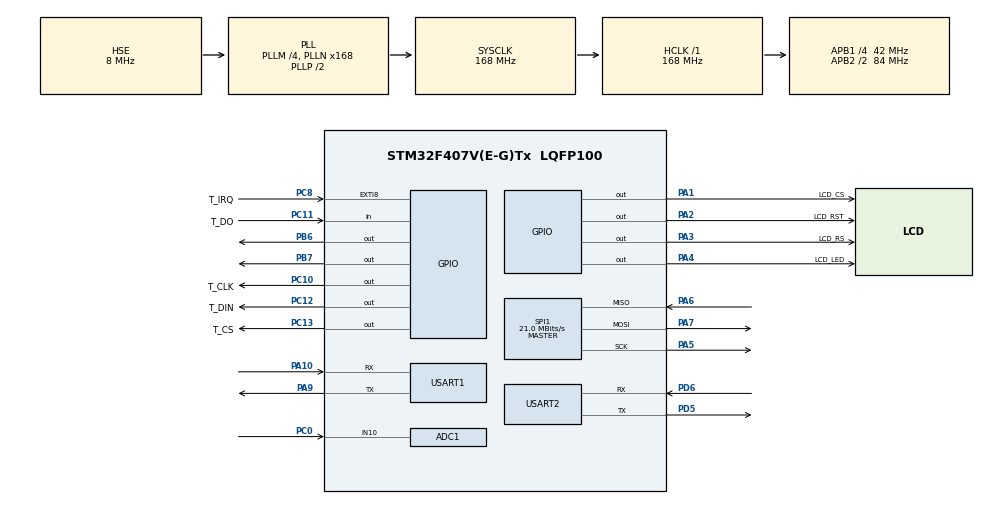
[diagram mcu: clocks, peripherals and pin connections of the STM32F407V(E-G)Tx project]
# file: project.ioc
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ADC1.Channel-0\#ChannelRegularConversion=ADC_CHANNEL_10
ADC1.NbrOfConversionFlag=1
ADC1.Rank-0\#ChannelRegularConversion=1
ADC1.SamplingTime-0\#ChannelRegularConversion=ADC_SAMPLETIME_3CYCLES
ADC1.master=1
Dma.Request0=USART1_TX
Dma.Request1=SPI1_TX
Dma.Request2=SPI1_RX
Dma.SPI1_RX.2.Direction=DMA_PERIPH_TO_MEMORY
Dma.SPI1_RX.2.FIFOMode=DMA_FIFOMODE_DISABLE
Dma.SPI1_RX.2.Instance=DMA2_Stream0
Dma.SPI1_RX.2.MemDataAlignment=DMA_MDATAALIGN_BYTE
Dma.SPI1_RX.2.MemInc=DMA_MINC_ENABLE
Dma.SPI1_RX.2.Mode=DMA_NORMAL
Dma.SPI1_RX.2.PeriphDataAlignment=DMA_PDATAALIGN_BYTE
Dma.SPI1_RX.2.PeriphInc=DMA_PINC_DISABLE
Dma.SPI1_RX.2.Priority=DMA_PRIORITY_MEDIUM
Dma.SPI1_TX.1.Direction=DMA_MEMORY_TO_PERIPH
Dma.SPI1_TX.1.FIFOMode=DMA_FIFOMODE_DISABLE
Dma.SPI1_TX.1.Instance=DMA2_Stream3
Dma.SPI1_TX.1.MemDataAlignment=DMA_MDATAALIGN_BYTE
Dma.SPI1_TX.1.MemInc=DMA_MINC_ENABLE
Dma.SPI1_TX.1.Mode=DMA_NORMAL
Dma.SPI1_TX.1.PeriphDataAlignment=DMA_PDATAALIGN_BYTE
Dma.SPI1_TX.1.PeriphInc=DMA_PINC_DISABLE
Dma.SPI1_TX.1.Priority=DMA_PRIORITY_MEDIUM
Dma.USART1_TX.0.Direction=DMA_MEMORY_TO_PERIPH
Dma.USART1_TX.0.FIFOMode=DMA_FIFOMODE_DISABLE
Dma.USART1_TX.0.Instance=DMA2_Stream7
Dma.USART1_TX.0.MemDataAlignment=DMA_MDATAALIGN_BYTE
Dma.USART1_TX.0.MemInc=DMA_MINC_ENABLE
Dma.USART1_TX.0.Mode=DMA_NORMAL
Dma.USART1_TX.0.PeriphDataAlignment=DMA_PDATAALIGN_BYTE
Dma.USART1_TX.0.PeriphInc=DMA_PINC_DISABLE
Dma.USART1_TX.0.Priority=DMA_PRIORITY_MEDIUM
Mcu.Family=STM32F4
Mcu.Name=STM32F407V(E-G)Tx
Mcu.Package=LQFP100
NVIC.DMA2_Stream0_IRQn=true\:5\:0\:true\:false\:true\:true\:false\:true
NVIC.DMA2_Stream3_IRQn=true\:5\:0\:true\:false\:true\:true\:false\:true
NVIC.DMA2_Stream7_IRQn=true\:5\:0\:true\:false\:true\:true\:false\:true
NVIC.EXTI9_5_IRQn=true\:6\:0\:true\:false\:true\:true\:true\:true
NVIC.PriorityGroup=NVIC_PRIORITYGROUP_4
NVIC.SPI1_IRQn=true\:3\:0\:true\:false\:true\:false\:true\:true
NVIC.TIM1_BRK_TIM9_IRQn=true\:1\:0\:true\:false\:true\:false\:true\:true
NVIC.TIM3_IRQn=true\:5\:0\:true\:false\:true\:true\:true\:true
NVIC.TimeBase=TIM1_BRK_TIM9_IRQn
NVIC.TimeBaseIP=TIM9
NVIC.USART1_IRQn=true\:6\:0\:true\:false\:true\:true\:false\:true
PA1.GPIO_Label=LCD_CS
PA1.GPIO_ModeDefaultOutputPP=GPIO_MODE_OUTPUT_PP
PA1.GPIO_PuPd=GPIO_NOPULL
PA1.GPIO_Speed=GPIO_SPEED_FREQ_VERY_HIGH
PA1.PinState=GPIO_PIN_SET
PA1.Signal=GPIO_Output
PA10.Mode=Asynchronous
PA10.Signal=USART1_RX
PA13.Mode=Serial_Wire
PA13.Signal=SYS_JTMS-SWDIO
PA14.Mode=Serial_Wire
PA14.Signal=SYS_JTCK-SWCLK
PA2.GPIO_Label=LCD_RST
PA2.GPIO_ModeDefaultOutputPP=GPIO_MODE_OUTPUT_PP
PA2.GPIO_PuPd=GPIO_NOPULL
PA2.GPIO_Speed=GPIO_SPEED_FREQ_VERY_HIGH
PA2.PinState=GPIO_PIN_SET
PA2.Signal=GPIO_Output
PA3.GPIO_Label=LCD_RS
PA3.GPIO_ModeDefaultOutputPP=GPIO_MODE_OUTPUT_PP
PA3.GPIO_PuPd=GPIO_NOPULL
PA3.GPIO_Speed=GPIO_SPEED_FREQ_VERY_HIGH
PA3.PinState=GPIO_PIN_SET
PA3.Signal=GPIO_Output
PA4.GPIO_Label=LCD_LED
PA4.GPIO_ModeDefaultOutputPP=GPIO_MODE_OUTPUT_PP
PA4.GPIO_PuPd=GPIO_NOPULL
PA4.GPIO_Speed=GPIO_SPEED_FREQ_VERY_HIGH
PA4.PinState=GPIO_PIN_SET
PA4.Signal=GPIO_Output
PA5.GPIO_PuPd=GPIO_PULLUP
PA5.Mode=Full_Duplex_Master
PA5.Signal=SPI1_SCK
PA6.GPIO_PuPd=GPIO_PULLUP
PA6.Mode=Full_Duplex_Master
PA6.Signal=SPI1_MISO
PA7.GPIO_PuPd=GPIO_PULLUP
PA7.Mode=Full_Duplex_Master
PA7.Signal=SPI1_MOSI
PA9.Mode=Asynchronous
PA9.Signal=USART1_TX
PB6.GPIO_ModeDefaultOutputPP=GPIO_MODE_OUTPUT_OD
PB6.GPIO_PuPd=GPIO_PULLUP
PB6.Signal=GPIO_Output
PB7.GPIO_ModeDefaultOutputPP=GPIO_MODE_OUTPUT_OD
PB7.GPIO_PuPd=GPIO_PULLUP
PB7.Signal=GPIO_Output
PC0.Signal=ADCx_IN10
PC10.GPIO_Label=T_CLK
PC10.GPIO_ModeDefaultOutputPP=GPIO_MODE_OUTPUT_PP
PC10.GPIO_Speed=GPIO_SPEED_FREQ_HIGH
PC10.PinState=GPIO_PIN_SET
PC10.Signal=GPIO_Output
PC11.GPIO_Label=T_DO
PC11.GPIO_PuPd=GPIO_PULLUP
PC11.Signal=GPIO_Input
PC12.GPIO_Label=T_DIN
PC12.GPIO_ModeDefaultOutputPP=GPIO_MODE_OUTPUT_PP
PC12.GPIO_Speed=GPIO_SPEED_FREQ_HIGH
PC12.PinState=GPIO_PIN_SET
PC12.Signal=GPIO_Output
PC13-ANTI_TAMP.GPIO_Label=T_CS
PC13-ANTI_TAMP.GPIO_ModeDefaultOutputPP=GPIO_MODE_OUTPUT_PP
PC13-ANTI_TAMP.GPIO_Speed=GPIO_SPEED_FREQ_HIGH
PC13-ANTI_TAMP.PinState=GPIO_PIN_SET
PC13-ANTI_TAMP.Signal=GPIO_Output
PC8.GPIO_Label=T_IRQ
PC8.GPIO_ModeDefaultEXTI=GPIO_MODE_IT_FALLING
PC8.GPIO_PuPd=GPIO_PULLUP
PC8.Signal=GPXTI8
PD5.Mode=Asynchronous
PD5.Signal=USART2_TX
PD6.Mode=Asynchronous
PD6.Signal=USART2_RX
PH0-OSC_IN.Mode=HSE-External-Oscillator
PH0-OSC_IN.Signal=RCC_OSC_IN
PH1-OSC_OUT.Mode=HSE-External-Oscillator
PH1-OSC_OUT.Signal=RCC_OSC_OUT
ProjectManager.HeapSize=0x400
ProjectManager.StackSize=0x1000
ProjectManager.TargetToolchain=MDK-ARM V5.32
RCC.48MHZClocksFreq_Value=84000000
RCC.AHBFreq_Value=168000000
RCC.APB1CLKDivider=RCC_HCLK_DIV4
RCC.APB1Freq_Value=42000000
RCC.APB1TimFreq_Value=84000000
RCC.APB2CLKDivider=RCC_HCLK_DIV2
RCC.APB2Freq_Value=84000000
RCC.APB2TimFreq_Value=168000000
RCC.CortexFreq_Value=168000000
RCC.HCLKFreq_Value=168000000
RCC.HSE_VALUE=8000000
RCC.HSI_VALUE=16000000
RCC.LSE_VALUE=32768
RCC.PLLM=4
RCC.PLLN=168
RCC.PLLSourceVirtual=RCC_PLLSOURCE_HSE
RCC.SYSCLKFreq_VALUE=168000000
RCC.SYSCLKSource=RCC_SYSCLKSOURCE_PLLCLK
RCC.VCOOutputFreq_Value=336000000
SH.ADCx_IN10.0=ADC1_IN10,IN10
SPI1.BaudRatePrescaler=SPI_BAUDRATEPRESCALER_4
SPI1.CLKPhase=SPI_PHASE_1EDGE
SPI1.CLKPolarity=SPI_POLARITY_LOW
SPI1.CRCCalculation=SPI_CRCCALCULATION_DISABLE
SPI1.CalculateBaudRate=21.0 MBits/s
SPI1.Direction=SPI_DIRECTION_2LINES
SPI1.FirstBit=SPI_FIRSTBIT_MSB
SPI1.Mode=SPI_MODE_MASTER
SPI1.NSS=SPI_NSS_SOFT
SPI1.TIMode=SPI_TIMODE_DISABLE
SPI1.VirtualType=VM_MASTER
TIM3.AutoReloadPreload=TIM_AUTORELOAD_PRELOAD_ENABLE
TIM3.Period=1000-1
TIM3.Prescaler=84-1
USART1.VirtualMode=VM_ASYNC
USART2.VirtualMode=VM_ASYNC
VP_SYS_VS_tim9.Mode=TIM9
VP_TIM3_VS_ClockSourceINT.Mode=Internal
board=custom

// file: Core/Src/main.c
/* USER CODE BEGIN Header */
/**
 ******************************************************************************

 ******************************************************************************
 */
/* USER CODE END Header */
#include "main.h"
#include "adc.h"
#include "dma.h"
#include "spi.h"
#include "tim.h"
#include "usart.h"
#include "gpio.h"

/* USER CODE BEGIN Includes */
#include "LCD.h"
#include "lvgl.h"
#include "lv_port_disp.h"
#include "lv_port_indev.h"
#include "lv_demos.h"
#include "touch.h"
#include "XPT2046.h"
#include "ui_demo_01.h"
#include "user_task.h"
/* USER CODE END Includes */

void SystemClock_Config(void);

int main(void)
{

  /* MCU Configuration--------------------------------------------------------*/

  /* Reset of all peripherals, Initializes the Flash interface and the Systick. */
  HAL_Init();

  /* Configure the system clock */
  SystemClock_Config();

  /* Initialize all configured peripherals */
  MX_GPIO_Init();
  MX_DMA_Init();
  MX_USART1_UART_Init();
  MX_TIM3_Init();
  MX_SPI1_Init();
  MX_ADC1_Init();
  MX_USART2_UART_Init();
  /* USER CODE BEGIN 2 */
  HAL_TIM_Base_Start_IT(&htim3); // 启动定时器3，1ms中断，作为LVGL时基

  freertos_start(); // 启动FreeRTOS，创建任务并启动调度器

  /* USER CODE END 2 */

  /* Infinite loop */
  while (1)
  {

  }
}

void SystemClock_Config(void)
{
  RCC_OscInitTypeDef RCC_OscInitStruct = {0};
  RCC_ClkInitTypeDef RCC_ClkInitStruct = {0};

  /** Configure the main internal regulator output voltage
  */
  __HAL_RCC_PWR_CLK_ENABLE();
  __HAL_PWR_VOLTAGESCALING_CONFIG(PWR_REGULATOR_VOLTAGE_SCALE1);

  /** Initializes the RCC Oscillators according to the specified parameters
  * in the RCC_OscInitTypeDef structure.
  */
  RCC_OscInitStruct.OscillatorType = RCC_OSCILLATORTYPE_HSE;
  RCC_OscInitStruct.HSEState = RCC_HSE_ON;
  RCC_OscInitStruct.PLL.PLLState = RCC_PLL_ON;
  RCC_OscInitStruct.PLL.PLLSource = RCC_PLLSOURCE_HSE;
  RCC_OscInitStruct.PLL.PLLM = 4;
  RCC_OscInitStruct.PLL.PLLN = 168;
  RCC_OscInitStruct.PLL.PLLP = RCC_PLLP_DIV2;
  RCC_OscInitStruct.PLL.PLLQ = 4;
  if (HAL_RCC_OscConfig(&RCC_OscInitStruct) != HAL_OK)
  {
    Error_Handler();
  }

  /** Initializes the CPU, AHB and APB buses clocks
  */
  RCC_ClkInitStruct.ClockType = RCC_CLOCKTYPE_HCLK|RCC_CLOCKTYPE_SYSCLK
                              |RCC_CLOCKTYPE_PCLK1|RCC_CLOCKTYPE_PCLK2;
  RCC_ClkInitStruct.SYSCLKSource = RCC_SYSCLKSOURCE_PLLCLK;
  RCC_ClkInitStruct.AHBCLKDivider = RCC_SYSCLK_DIV1;
  RCC_ClkInitStruct.APB1CLKDivider = RCC_HCLK_DIV4;
  RCC_ClkInitStruct.APB2CLKDivider = RCC_HCLK_DIV2;

  if (HAL_RCC_ClockConfig(&RCC_ClkInitStruct, FLASH_LATENCY_5) != HAL_OK)
  {
    Error_Handler();
  }
}

void HAL_TIM_PeriodElapsedCallback(TIM_HandleTypeDef *htim)
{
  if (htim->Instance == TIM9) {
    HAL_IncTick();
  }
  /* USER CODE BEGIN Callback 1 */
	if (htim->Instance == TIM3)
  {
    lv_tick_inc(1); //LVGL时基，每1ms调用一次
  }
  /* USER CODE END Callback 1 */
}

void Error_Handler(void)
{
  __disable_irq();
  while (1)
  {
  }
}
